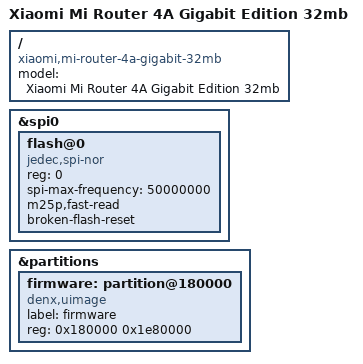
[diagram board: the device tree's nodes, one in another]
// SPDX-License-Identifier: GPL-2.0-or-later OR MIT

#include "mt7621_xiaomi_mi-router-4a-3g-v2.dtsi"

/ {
	compatible = "xiaomi,mi-router-4a-gigabit-32mb", "mediatek,mt7621-soc";
	model = "Xiaomi Mi Router 4A Gigabit Edition 32mb";

};

&spi0 {
	status = "okay";

	flash@0 {
		compatible = "jedec,spi-nor";
		reg = <0>;
		spi-max-frequency = <50000000>;
		m25p,fast-read;
	broken-flash-reset;
	};
};

&partitions {
	firmware: partition@180000 {
		compatible = "denx,uimage";
		label = "firmware";
		reg = <0x180000 0x1e80000>;
	};
};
